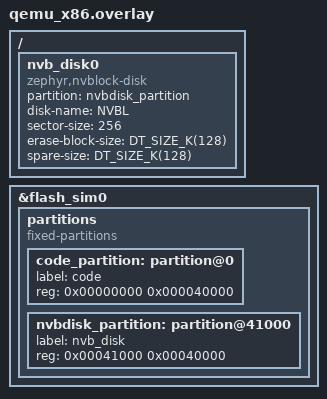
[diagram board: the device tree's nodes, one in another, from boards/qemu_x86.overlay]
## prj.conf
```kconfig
CONFIG_DISK_ACCESS=y
#CONFIG_DISK_DRIVERS=y
CONFIG_DISK_DRIVER_NVBLOCK=y
CONFIG_FLASH=y
CONFIG_MAIN_STACK_SIZE=4096
#CONFIG_PICOLIBC=y

# Compile for code partition
CONFIG_USE_DT_CODE_PARTITION=y

# Logging
CONFIG_LOG=y
CONFIG_LOG_MODE_MINIMAL=y
```

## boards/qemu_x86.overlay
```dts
/*
 * Copyright (c) 2022 Laczen
 *
 * SPDX-License-Identifier: Apache-2.0
 */

&flash_sim0 {
	partitions {
		compatible = "fixed-partitions";
		#address-cells = <1>;
		#size-cells = <1>;

		code_partition: partition@0 {
			label = "code";
			reg = <0x00000000 0x000040000>;
		};

		nvbdisk_partition: partition@41000 {
			label = "nvb_disk";
			reg = <0x00041000 0x00040000>;
		};

	};
};

/ {
	nvb_disk0 {
		compatible = "zephyr,nvblock-disk";
                status = "okay";
		partition = <&nvbdisk_partition>;
		disk-name = "NVBL";
		sector-size = <256>;
                erase-block-size = <DT_SIZE_K(128)>;
		spare-size = <DT_SIZE_K(128)>;
	};
};
```

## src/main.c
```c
/*
 * Copyright (c) 2012-2014 Wind River Systems, Inc.
 *
 * SPDX-License-Identifier: Apache-2.0
 */

#include <zephyr/kernel.h>
#include <zephyr/storage/disk_access.h>

static const char *disk_pdrv = "NVBL";
static uint32_t disk_sector_count;
static uint32_t disk_sector_size;

void main(void)
{
        int rc;

	printk("Hello World! %s\n", CONFIG_BOARD);
        rc = disk_access_init(disk_pdrv);
        printk("Init returned %d\n", rc);
        rc = disk_access_ioctl(disk_pdrv, 0x01, &disk_sector_count);
        printk("Disk has %d sectors\n", disk_sector_count);
        rc = disk_access_ioctl(disk_pdrv, 0x02, &disk_sector_size);
        printk("Disk has sectors of %d byte\n", disk_sector_size);
}
```
